# ATA6285 device description
Architecture: AVR8; Family: megaAVR
Registers are 8-bit, access not given, no defined reset value unless marked. A register's access mark holds for its fields unless they carry their own. Offsets are from the block's base; [hi:lo] are bit positions.

## LOCKBIT
Instances: LOCKBIT 0 in lockbits
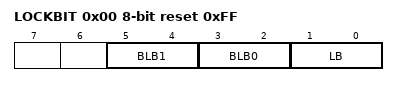
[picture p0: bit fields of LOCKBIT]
0x00 LOCKBIT reset 0xFF
  [5:4] BLB1 — Boot Loader Protection Mode
    0=LPM_AND_SPM_PROHIBITED_IN_BOOT_SECTION; 1=LPM_PROHIBITED_IN_BOOT_SECTION; 2=SPM_PROHIBITED_IN_BOOT_SECTION; 3=NO_LOCK_ON_SPM_AND_LPM_IN_BOOT_SECTION
  [3:2] BLB0 — Boot Loader Protection Mode
    0=LPM_AND_SPM_PROHIBITED_IN_APPLICATION_SECTION; 1=LPM_PROHIBITED_IN_APPLICATION_SECTION; 2=SPM_PROHIBITED_IN_APPLICATION_SECTION; 3=NO_LOCK_ON_SPM_AND_LPM_IN_APPLICATION_SECTION
  [1:0] LB — Memory Lock
    0=PROG_VER_DISABLED (Further programming and verification disabled); 2=PROG_DISABLED (Further programming disabled); 3=NO_LOCK (No memory lock features enabled)

## SENSOR_INTERFACE
Instances: SENSOR_INTERFACE 0x00
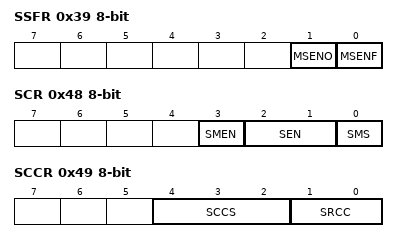
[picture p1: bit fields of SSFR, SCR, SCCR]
0x39 SSFR — Sensor Status + Flag Register
  [1] MSENO — Motion Sensor Output
  [0] MSENF — Motion Sensor Flag
0x47 SVCR bits used 4:0 — Sensor Voltage Control Register
0x48 SCR — Sensor Control Register
  [3] SMEN — Sensor Motion Enable Bit
  [2:1] SEN — Sensor enable Bits
  [0] SMS — Sensor Measurement Start Bit
0x49 SCCR — Sensor Capacitor Control Register
  [4:2] SCCS — Sensor Capacitor Channel Select Bit2
  [1:0] SRCC — Sensor Reference Charge Current Bit1
0x61 SIMSK — Sensor Interrupt Mask register
  [0] MSIE — Motion Sensor Interrupt Enable Bit
0x64 TSCR — Temperature Sensor Control Register
  [0] TSSD — Temperature Sensor Shutdown mode Disable
0x67 MSVCAL — Motion Sensor Voltage Calibration Register

## SPI
Instances: SPI 0x00
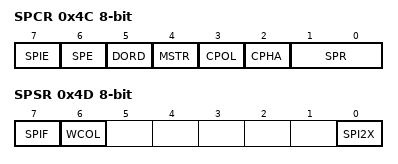
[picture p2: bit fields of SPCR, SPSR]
0x4C SPCR — SPI Control Register
  [7] SPIE — SPI Interrupt Enable
  [6] SPE — SPI Enable
  [5] DORD — Data Order
  [4] MSTR — Master/Slave Select
  [3] CPOL — Clock polarity
  [2] CPHA — Clock Phase
  [1:0] SPR — SPI Clock Rate Selects
    0=FOSC_4; 1=FOSC_16; 2=FOSC_64; 3=FOSC_128; 4=FOSC_2; 5=FOSC_8; 6=FOSC_32; 7=FOSC_64
0x4D SPSR — SPI Status Register
  [7] SPIF — SPI Interrupt Flag
  [6] WCOL — Write Collision Flag
  [0] SPI2X — Double SPI Speed Bit
0x4E SPDR — SPI Data Register

## CPU
Instances: CPU 0x00
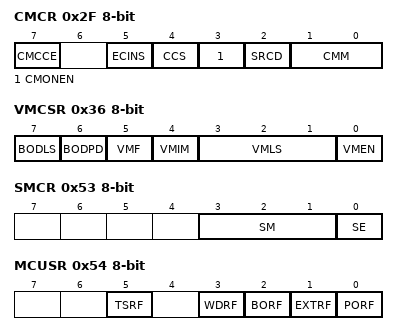
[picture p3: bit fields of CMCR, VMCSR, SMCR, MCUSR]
0x2F CMCR — Clock Management Control Register
  [7] CMCCE — Clock Management Control Change Enable Bit
  [5] ECINS — External Clock Input Select Bit
  [4] CCS — Core Clock Select Bit
  [3] CMONEN — Clock Monitoring Enable
  [2] SRCD — Slow RC-oscillator Disable Bit
  [1:0] CMM — Clock Management Mode Bitss
0x30 CMSR — Clock Management Status Register
  [0] ECF — External Clock input Flag Bit
0x36 VMCSR — Voltage Monitor Control and Status Register
  [7] BODLS — Brown-Out Detection Level Select Bit
  [6] BODPD — Brown-Out Detection on Power-Down Bit
  [5] VMF — Voltage Monitor Flag
  [4] VMIM — Voltage Monitor Interrupt Mask Bit
  [3:1] VMLS — Voltage Monitor Level Select Bits
  [0] VMEN — Voltage Monitor Enable Bit
0x3E GPIOR0 — General Purpose I/O Register 0
0x4A GPIOR1 — General Purpose I/O Register 1
0x4B GPIOR2 — General Purpose I/O Register 2
0x53 SMCR — Sleep Mode Control Register
  [3:1] SM
    0=IDLE; 1=SENSORNR (Sensor Noise Reduction); 2=PDOWN (Power Down)
  [0] SE
0x54 MCUSR — MCU Status Register
  [5] TSRF — Temperature Shutdown Reset Flag
  [3] WDRF — Watchdog Reset Flag
  [2] BORF — Brown-out Reset Flag
  [1] EXTRF — External Reset Flag
  [0] PORF — Power-on reset flag
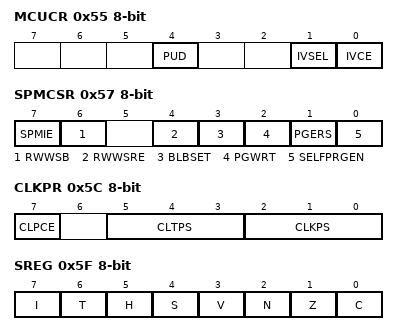
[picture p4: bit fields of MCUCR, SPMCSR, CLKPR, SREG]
0x55 MCUCR — MCU Control Register
  [4] PUD
  [1] IVSEL — Interrupt Vector Select
  [0] IVCE — Interrupt Vector Change Enable
0x57 SPMCSR — Store Program Memory Control Register
  [7] SPMIE — SPM Interrupt Enable
  [6] RWWSB — Read-While-Write Section Busy
  [4] RWWSRE — Read-While-Write section read enable
  [3] BLBSET — Boot Lock Bit Set
  [2] PGWRT — Page Write
  [1] PGERS — Page Erase
  [0] SELFPRGEN — Self Programming Enable
0x5B CMIMR — Clock Management Interrupt Mask Register
  [0] ECIE — External Clock input Interrupt Enable Bit
0x5C CLKPR — Clock Prescaler Register
  [7] CLPCE — Clock Prescaler Change Enable Bit
  [5:3] CLTPS — Clock Timer Prescaler Select Bits
  [2:0] CLKPS — Clock system Prescaler Select Bits
0x5D SP 16-bit — Stack Pointer
0x5F SREG — Status Register
  [7] I — Global Interrupt Enable
  [6] T — Bit Copy Storage
  [5] H — Half Carry Flag
  [4] S — Sign Bit
  [3] V — Two's Complement Overflow Flag
  [2] N — Negative Flag
  [1] Z — Zero Flag
  [0] C — Carry Flag
0x65 SRCCAL — SRC-Oscillator Calibration Register
0x66 FRCCAL bits used 5:0 — FRC-Oscillator Calibration Register
